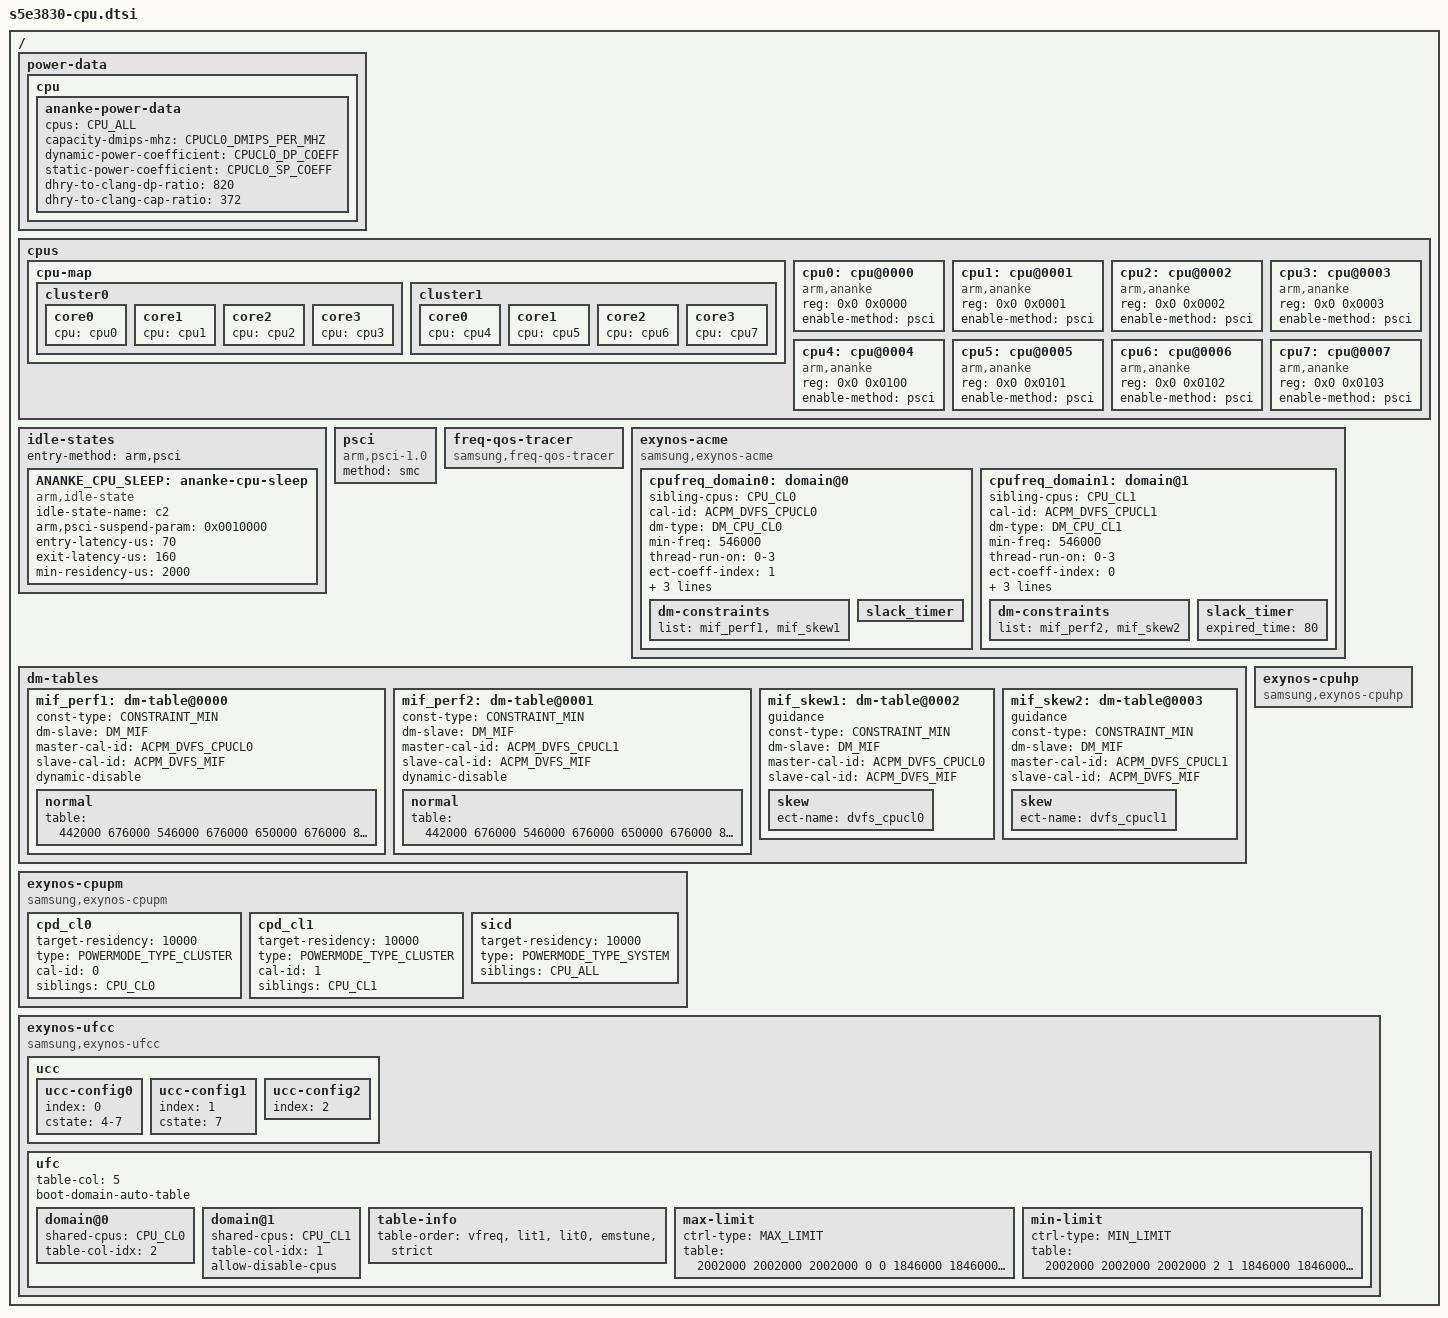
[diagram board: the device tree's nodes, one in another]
/*
 * SAMSUNG S5E3830 SoC CPU device tree source
 *
 * Copyright (c) 2022 Samsung Electronics Co., Ltd.
 *             http://www.samsung.com
 *
 * SAMSUNG EXYNOS3830 SoC device nodes are listed in this file.
 * EXYNOS based board files can include this file and provide
 * values for board specfic bindings.
 *
 * This program is free software; you can redistribute it and/or modify
 * it under the terms of the GNU General Public License version 2 as
 * published by the Free Software Foundation.
 */

#include <dt-bindings/soc/samsung/cpupm.h>

/ {

	#define CPU_CL0 "0-3"
	#define CPU_CL1 "4-7"
	#define CPU_ALL "0-7"

	power-data {
		#define CPUCL0_DMIPS_PER_MHZ 271
		#define CPUCL0_DP_COEFF 125
		#define CPUCL0_SP_COEFF 10

		cpu {
			ananke-power-data {
				/* default power data */
				cpus = CPU_ALL;
				capacity-dmips-mhz = <CPUCL0_DMIPS_PER_MHZ>;
				dynamic-power-coefficient = <CPUCL0_DP_COEFF>;
				static-power-coefficient = <CPUCL0_SP_COEFF>;

				/* dhrystone to clang conversion ratio */
				dhry-to-clang-dp-ratio = <820>;
				dhry-to-clang-cap-ratio = <372>;
			};
		};
	};

	cpus {
		#address-cells = <2>;
		#size-cells = <0>;

		cpu-map {
			cluster0 {
				core0 {
					cpu = <&cpu0>;
				};
				core1 {
					cpu = <&cpu1>;
				};
				core2 {
					cpu = <&cpu2>;
				};
				core3 {
					cpu = <&cpu3>;
				};
			};

			cluster1 {
				core0 {
					cpu = <&cpu4>;
				};
				core1 {
					cpu = <&cpu5>;
				};
				core2 {
					cpu = <&cpu6>;
				};
				core3 {
					cpu = <&cpu7>;
				};
			};
		};

		cpu0: cpu@0000 {
			device_type = "cpu";
			compatible = "arm,ananke", "arm,armv8";
			reg = <0x0 0x0000>;
			enable-method = "psci";
		};
		cpu1: cpu@0001 {
			device_type = "cpu";
			compatible = "arm,ananke", "arm,armv8";
			reg = <0x0 0x0001>;
			enable-method = "psci";
		};
		cpu2: cpu@0002 {
			device_type = "cpu";
			compatible = "arm,ananke", "arm,armv8";
			reg = <0x0 0x0002>;
			enable-method = "psci";
		};
		cpu3: cpu@0003 {
			device_type = "cpu";
			compatible = "arm,ananke", "arm,armv8";
			reg = <0x0 0x0003>;
			enable-method = "psci";
		};
		cpu4: cpu@0004 {
			device_type = "cpu";
			compatible = "arm,ananke", "arm,armv8";
			reg = <0x0 0x0100>;
			enable-method = "psci";
		};
		cpu5: cpu@0005 {
			device_type = "cpu";
			compatible = "arm,ananke", "arm,armv8";
			reg = <0x0 0x0101>;
			enable-method = "psci";
		};
		cpu6: cpu@0006 {
			device_type = "cpu";
			compatible = "arm,ananke", "arm,armv8";
			reg = <0x0 0x0102>;
			enable-method = "psci";
		};
		cpu7: cpu@0007 {
			device_type = "cpu";
			compatible = "arm,ananke", "arm,armv8";
			reg = <0x0 0x0103>;
			enable-method = "psci";
		};
	};

	idle-states {
		entry-method = "arm,psci";

		ANANKE_CPU_SLEEP: ananke-cpu-sleep {
			  idle-state-name = "c2";
			  compatible = "arm,idle-state";
			  arm,psci-suspend-param = <0x0010000>;
			  entry-latency-us = <70>;
			  exit-latency-us = <160>;
			  min-residency-us = <2000>;
			  status = "okay";
		  };
	};

	psci {
		compatible = "arm,psci-1.0";
		method = "smc";
	};

	freq-qos-tracer {
		compatible = "samsung,freq-qos-tracer";
		status = "okay";
	};

	exynos-acme {
		compatible = "samsung,exynos-acme";
		status = "okay";

		cpufreq_domain0: domain@0 {
			sibling-cpus = CPU_CL0;
			cal-id = <ACPM_DVFS_CPUCL0>;
			dm-type = <DM_CPU_CL0>;
			//dss-type = <ESS_FLAG_CPU_CL0>;

			//max-freq = <1508000>;
			min-freq = <546000>;

			thread-run-on = "0-3";

			#cooling-cells = <2>; /* min followed by max */
			ect-coeff-index = <1>;
			tz-cooling-name = "LITTLE";

			freq-table = <  442000
					546000
					650000
					806000
					949000
					1053000
					1157000
					1300000
					1456000
					1586000
					1742000
					1846000
					2002000 >;

			dm-constraints {
				list = <&mif_perf1>,
					<&mif_skew1>;
			};

			slack_timer {
				device_type = "slack-timer-domain";
			};
		};

		cpufreq_domain1: domain@1 {
			sibling-cpus = CPU_CL1;
			cal-id = <ACPM_DVFS_CPUCL1>;
			dm-type = <DM_CPU_CL1>;
			//dss-type = <ESS_FLAG_CPU_CL1>;

			//max-freq = <1872000>;
			min-freq = <546000>;

			thread-run-on = "0-3";

			#cooling-cells = <2>; /* min followed by max */
			ect-coeff-index = <0>;
			tz-cooling-name = "LITTLE";

			freq-table = <  442000
					546000
					650000
					806000
					949000
					1053000
					1157000
					1300000
					1456000
					1586000
					1742000
					1846000
					2002000 >;

			 dm-constraints {
				 list = <&mif_perf2>,
					<&mif_skew2>;
			};

			slack_timer {
				device_type = "slack-timer-domain";
				expired_time = <80>;    /* 80ms */ 
			};
		 };
	};

	dm-tables {
		mif_perf1: dm-table@0000 {
			const-type = <CONSTRAINT_MIN>;
			dm-slave = <DM_MIF>;
			master-cal-id = <ACPM_DVFS_CPUCL0>;
			slave-cal-id = <ACPM_DVFS_MIF>;
			dynamic-disable;

			normal {	/* CPU    MIF */
				table = < 442000   676000
					  546000   676000
					  650000   676000
					  806000   676000
					  949000   676000
					 1053000   845000
					 1157000   845000
					 1300000  1014000
					 1456000  1014000
					 1586000  1352000
					 1742000  1352000
					 1846000  1539000
					 2002000  1539000 >;
			};
		};
		mif_perf2: dm-table@0001 {
			const-type = <CONSTRAINT_MIN>;
			dm-slave = <DM_MIF>;
			master-cal-id = <ACPM_DVFS_CPUCL1>;
			slave-cal-id = <ACPM_DVFS_MIF>;
			dynamic-disable;

			normal {        /* CPU    MIF */
				table = < 442000   676000
					  546000   676000
					  650000   676000
					  806000   676000
					  949000   676000
					 1053000   845000
					 1157000   845000
					 1300000  1014000
					 1456000  1014000
					 1586000  1352000
					 1742000  1352000
					 1846000  1539000
					 2002000  1539000 >;
			};
		};
		mif_skew1: dm-table@0002 {
			guidance;
			const-type = <CONSTRAINT_MIN>;
			dm-slave = <DM_MIF>;
			master-cal-id = <ACPM_DVFS_CPUCL0>;
			slave-cal-id = <ACPM_DVFS_MIF>;
			skew {
				ect-name = "dvfs_cpucl0";
			};
		};
		mif_skew2: dm-table@0003 {
			guidance;
			const-type = <CONSTRAINT_MIN>;
			dm-slave = <DM_MIF>;
			master-cal-id = <ACPM_DVFS_CPUCL1>;
			slave-cal-id = <ACPM_DVFS_MIF>;
			skew {
				ect-name = "dvfs_cpucl1";
			};
		};
	};

	exynos-cpupm {
		compatible = "samsung,exynos-cpupm";
		status = "okay";

		cpd_cl0 {
			device_type ="cpupm";
			target-residency = <10000>;
			type = <POWERMODE_TYPE_CLUSTER>;
			cal-id = <0>;
			siblings = CPU_CL0;
		};

		cpd_cl1 {
			device_type = "cpupm";
			target-residency = <10000>;
			type = <POWERMODE_TYPE_CLUSTER>;
			cal-id = <1>;
			siblings = CPU_CL1;
		};

		sicd {
			device_type = "cpupm";
			target-residency = <10000>;
			type = <POWERMODE_TYPE_SYSTEM>;
			siblings = CPU_ALL;
		};
	};

	exynos-cpuhp {
		compatible = "samsung,exynos-cpuhp";
		status = "okay";
	};

	exynos-ufcc {
		compatible = "samsung,exynos-ufcc";
		status = "okay";

		ucc {
			ucc-config0 {
				index = <0>;
				cstate = "4-7";
			};
			ucc-config1 {
				index = <1>;
				cstate = "7";
			};
			ucc-config2 {
				index = <2>;
			};
		};

		ufc {
			/* Ctrl Type */
			#define MIN_LIMIT               0
			#define MIN_LIMIT_WO_BOOST      1
			#define MAX_LIMIT               2

			table-col = <5>;
			boot-domain-auto-table;

			domain@0 {
				device_type = "ufc-domain";
				shared-cpus = CPU_CL0;
				table-col-idx = <2>;
			};
			domain@1 {
				device_type = "ufc-domain";
				shared-cpus = CPU_CL1;
				table-col-idx = <1>;
				allow-disable-cpus;
			};

			table-info {
				table-order = "vfreq",
					"lit1",
					"lit0",
					"emstune",
					"strict";
			};

			max-limit {
				device_type = "ufc-table";
				ctrl-type = <MAX_LIMIT>;
				/* VFREQ    LIT1   LIT0   EMS STRICT */
				table = < 2002000 2002000 2002000 0 0
					  1846000 1846000 1846000 0 0
					  1742000 1742000 1742000 0 0
					  1586000 1586000 1586000 0 0
					  1456000 1456000 1456000 0 0
					  1300000 1300000 1300000 0 0
					  1157000 1157000 1157000 0 0
					  1053000 1053000 1053000 0 0
					   949000  949000  949000 0 0
					   806000  806000  806000 0 0
					   650000  650000  650000 0 0
					   546000  546000  546000 0 0 >;
				/* filled little freq automatically */
			};
			min-limit {
				device_type = "ufc-table";
				ctrl-type = <MIN_LIMIT>;

				/* VFREQ   LIT1     LIT0   EMS STRICT */
				table = < 2002000 2002000 2002000 2 1
					  1846000 1846000 1846000 1 1
					  1742000 1742000 1742000 1 1
					  1586000 1586000 1586000 1 1
					  1456000 1456000 1456000 1 1
					  1300000 1300000 1300000 1 1
					  1157000 1157000 1157000 1 1
					  1053000 1053000 1053000 1 1
					   949000  949000  949000 1 1
					   806000  806000  806000 1 1
					   650000  650000  650000 0 1
					   546000  546000  546000 0 1 >;
				/* filled little freq automatically */
			};
		};
	};

};
